AUTOSAR XML (schema 4-2-2)
package /ComponentTypes
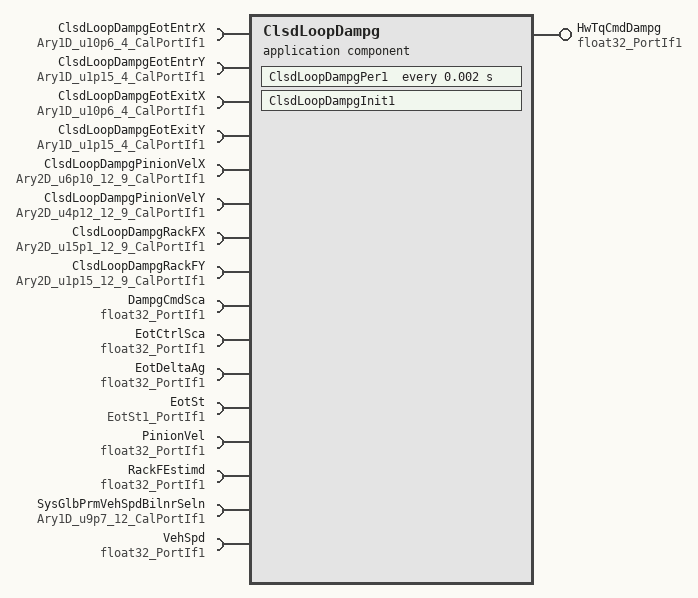
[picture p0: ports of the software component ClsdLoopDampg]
  application sw component type ClsdLoopDampg
    provide port HwTqCmdDampg: nonqueued-sender-com-spec{data-element=Val, init-value=0}, provided-interface=float32_PortIf1
    16 x require port:
      ClsdLoopDampgEotEntrX: parameter-require-com-spec{init-value=[0, 448, 3008, 3520], parameter=Ary1D}, required-interface=Ary1D_u10p6_4_CalPortIf1
      ClsdLoopDampgEotEntrY: parameter-require-com-spec{init-value=[557, 557, 0, 0], parameter=Ary1D}, required-interface=Ary1D_u1p15_4_CalPortIf1
      ClsdLoopDampgEotExitX: parameter-require-com-spec{init-value=[0, 448, 3008, 3520], parameter=Ary1D}, required-interface=Ary1D_u10p6_4_CalPortIf1
      ClsdLoopDampgEotExitY: parameter-require-com-spec{init-value=[557, 557, 0, 0], parameter=Ary1D}, required-interface=Ary1D_u1p15_4_CalPortIf1
      ClsdLoopDampgPinionVelX: parameter-require-com-spec{init-value=12 x [0, 89, 179, 357, 715, 1430, 2860, 5719, 8936], parameter=Ary2D}, required-interface=Ary2D_u6p10_12_9_CalPortIf1
      ClsdLoopDampgPinionVelY: parameter-require-com-spec{init-value=12 x [0, 64, 124, 288, 900, 2456, 5980, 12288, 12288], parameter=Ary2D}, required-interface=Ary2D_u4p12_12_9_CalPortIf1
      ClsdLoopDampgRackFX: parameter-require-com-spec{init-value=12 x [0, 394, 798, 1204, 1610, 2009, 2406, 2834, 29568], parameter=Ary2D}, required-interface=Ary2D_u15p1_12_9_CalPortIf1
      ClsdLoopDampgRackFY: parameter-require-com-spec{init-value=12 x 9 x 32768, parameter=Ary2D}, required-interface=Ary2D_u1p15_12_9_CalPortIf1
      DampgCmdSca: nonqueued-receiver-com-spec{data-element=Val, filter=data-filter-type=ALWAYS, init-value=1}, required-interface=float32_PortIf1
      EotCtrlSca: nonqueued-receiver-com-spec{data-element=Val, filter=data-filter-type=ALWAYS, init-value=0}, required-interface=float32_PortIf1
      EotDeltaAg: nonqueued-receiver-com-spec{data-element=Val, filter=data-filter-type=ALWAYS, init-value=900}, required-interface=float32_PortIf1
      EotSt: nonqueued-receiver-com-spec{data-element=Val, filter=data-filter-type=ALWAYS, init-value=0}, required-interface=EotSt1_PortIf1
      PinionVel: nonqueued-receiver-com-spec{data-element=Val, filter=data-filter-type=ALWAYS, init-value=0}, required-interface=float32_PortIf1
      RackFEstimd: nonqueued-receiver-com-spec{data-element=Val, filter=data-filter-type=ALWAYS, init-value=0}, required-interface=float32_PortIf1
      SysGlbPrmVehSpdBilnrSeln: parameter-require-com-spec{init-value=[0, 640, 1920, 3840, 7680, 10240, 12800, 15360, 19200, 23040, 25600, 28160], parameter=Ary1D}, required-interface=Ary1D_u9p7_12_CalPortIf1
      VehSpd: nonqueued-receiver-com-spec{data-element=Val, filter=data-filter-type=ALWAYS, init-value=0}, required-interface=float32_PortIf1
    behavior ClsdLoopDampg_InternalBehavior
      init event ClsdLoopDampg_InitEvent: start-on-event=ClsdLoopDampgInit1
      timing event TMT_ClsdLoopDampgPer1: start-on-event=ClsdLoopDampgPer1, period=0.002
      port-api-options:
        enable-take-address=false, error-handling=NO-TRANSFORMER-ERROR-HANDLING, indirect-api=false, port=ClsdLoopDampgEotEntrX
        enable-take-address=false, error-handling=NO-TRANSFORMER-ERROR-HANDLING, indirect-api=false, port=ClsdLoopDampgEotEntrY
        enable-take-address=false, error-handling=NO-TRANSFORMER-ERROR-HANDLING, indirect-api=false, port=ClsdLoopDampgEotExitX
        enable-take-address=false, error-handling=NO-TRANSFORMER-ERROR-HANDLING, indirect-api=false, port=ClsdLoopDampgEotExitY
        enable-take-address=false, error-handling=NO-TRANSFORMER-ERROR-HANDLING, indirect-api=false, port=ClsdLoopDampgPinionVelX
        enable-take-address=false, error-handling=NO-TRANSFORMER-ERROR-HANDLING, indirect-api=false, port=ClsdLoopDampgPinionVelY
        enable-take-address=false, error-handling=NO-TRANSFORMER-ERROR-HANDLING, indirect-api=false, port=ClsdLoopDampgRackFX
        enable-take-address=false, error-handling=NO-TRANSFORMER-ERROR-HANDLING, indirect-api=false, port=ClsdLoopDampgRackFY
        enable-take-address=false, error-handling=NO-TRANSFORMER-ERROR-HANDLING, indirect-api=false, port=DampgCmdSca
        enable-take-address=false, error-handling=NO-TRANSFORMER-ERROR-HANDLING, indirect-api=false, port=EotCtrlSca
        enable-take-address=false, error-handling=NO-TRANSFORMER-ERROR-HANDLING, indirect-api=false, port=EotDeltaAg
        enable-take-address=false, error-handling=NO-TRANSFORMER-ERROR-HANDLING, indirect-api=false, port=EotSt
        enable-take-address=false, error-handling=NO-TRANSFORMER-ERROR-HANDLING, indirect-api=false, port=HwTqCmdDampg
        enable-take-address=false, error-handling=NO-TRANSFORMER-ERROR-HANDLING, indirect-api=false, port=PinionVel
        enable-take-address=false, error-handling=NO-TRANSFORMER-ERROR-HANDLING, indirect-api=false, port=RackFEstimd
        enable-take-address=false, error-handling=NO-TRANSFORMER-ERROR-HANDLING, indirect-api=false, port=SysGlbPrmVehSpdBilnrSeln
        enable-take-address=false, error-handling=NO-TRANSFORMER-ERROR-HANDLING, indirect-api=false, port=VehSpd
      runnable ClsdLoopDampgInit1
      runnable ClsdLoopDampgPer1
        data-receive-point-by-arguments:
          7 x access:
            REC_DampgCmdSca_Val: accessed-variable=DampgCmdSca.Val
            REC_EotCtrlSca_Val: accessed-variable=EotCtrlSca.Val
            REC_EotDeltaAg_Val: accessed-variable=EotDeltaAg.Val
            REC_EotSt_Val: accessed-variable=EotSt.Val
            REC_PinionVel_Val: accessed-variable=PinionVel.Val
            REC_RackFEstimd_Val: accessed-variable=RackFEstimd.Val
            REC_VehSpd_Val: accessed-variable=VehSpd.Val
        data-send-points:
          access SEND_HwTqCmdDampg_Val: accessed-variable=HwTqCmdDampg.Val
  swc implementation ClsdLoopDampg_Implementation: behavior=ClsdLoopDampg_InternalBehavior
    code-descriptors:
      code Default: artifact-descriptors=autosar-engineering-object={short-label=Default, category=SWSRC}
